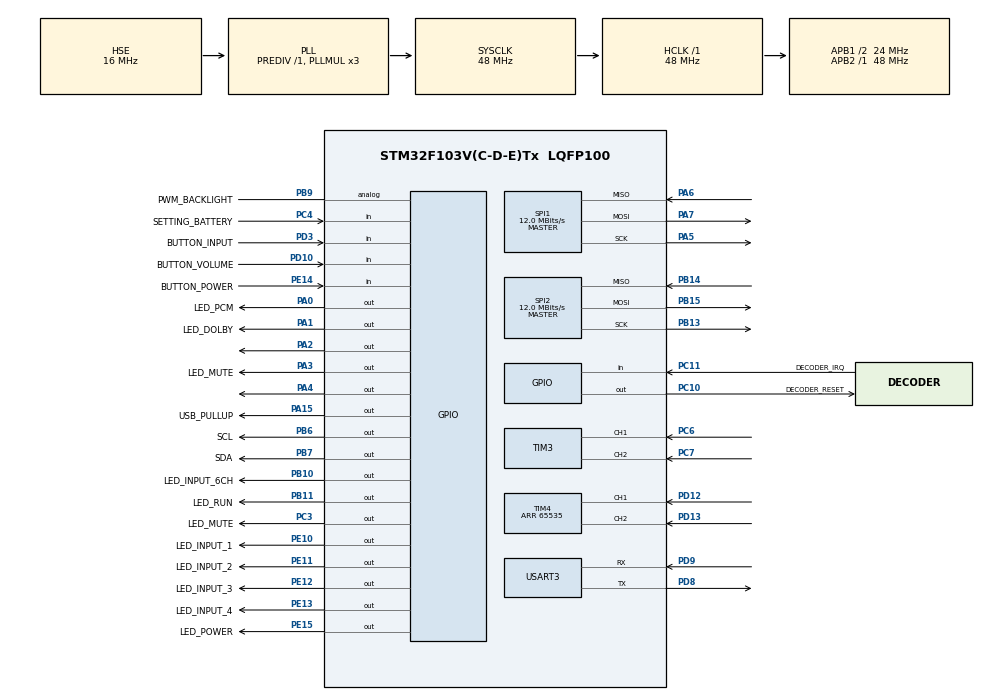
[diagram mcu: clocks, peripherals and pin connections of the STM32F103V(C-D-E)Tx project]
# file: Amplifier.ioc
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FREERTOS.Tasks01=defaultTask,24,256,StartDefaultTask,Default,NULL,Dynamic,NULL,NULL;audioThread,32,256,startAudio,Default,NULL,Dynamic,NULL,NULL
FREERTOS.configMINIMAL_STACK_SIZE=256
FREERTOS.configTOTAL_HEAP_SIZE=4096
FREERTOS.configUSE_NEWLIB_REENTRANT=1
Mcu.Family=STM32F1
Mcu.Name=STM32F103V(C-D-E)Tx
Mcu.Package=LQFP100
NVIC.PriorityGroup=NVIC_PRIORITYGROUP_4
NVIC.TIM3_IRQn=true\:5\:0\:false\:false\:true\:true\:true\:true\:true
NVIC.TIM4_IRQn=true\:5\:0\:false\:false\:true\:true\:true\:true\:true
OSC_IN.Mode=HSE-External-Oscillator
OSC_IN.Signal=RCC_OSC_IN
OSC_OUT.Mode=HSE-External-Oscillator
OSC_OUT.Signal=RCC_OSC_OUT
PA0-WKUP.GPIO_Label=LED_PCM
PA0-WKUP.Signal=GPIO_Output
PA1.GPIO_Label=LED_DOLBY
PA1.Signal=GPIO_Output
PA13.Mode=Serial_Wire
PA13.Signal=SYS_JTMS-SWDIO
PA14.Mode=Serial_Wire
PA14.Signal=SYS_JTCK-SWCLK
PA15.GPIO_Label=USB_PULLUP
PA15.Signal=GPIO_Output
PA2.Signal=GPIO_Output
PA3.GPIO_Label=LED_MUTE
PA3.Signal=GPIO_Output
PA4.Signal=GPIO_Output
PA5.Mode=Full_Duplex_Master
PA5.Signal=SPI1_SCK
PA6.Mode=Full_Duplex_Master
PA6.Signal=SPI1_MISO
PA7.Mode=Full_Duplex_Master
PA7.Signal=SPI1_MOSI
PB10.GPIO_Label=LED_INPUT_6CH
PB10.Signal=GPIO_Output
PB11.GPIO_Label=LED_RUN
PB11.Signal=GPIO_Output
PB13.Mode=Full_Duplex_Master
PB13.Signal=SPI2_SCK
PB14.Mode=Full_Duplex_Master
PB14.Signal=SPI2_MISO
PB15.Mode=Full_Duplex_Master
PB15.Signal=SPI2_MOSI
PB6.GPIO_Label=SCL
PB6.GPIO_ModeDefaultOutputPP=GPIO_MODE_OUTPUT_OD
PB6.GPIO_PuPd=GPIO_NOPULL
PB6.GPIO_Speed=GPIO_SPEED_FREQ_HIGH
PB6.PinState=GPIO_PIN_SET
PB6.Signal=GPIO_Output
PB7.GPIO_Label=SDA
PB7.GPIO_ModeDefaultOutputPP=GPIO_MODE_OUTPUT_OD
PB7.GPIO_PuPd=GPIO_NOPULL
PB7.GPIO_Speed=GPIO_SPEED_FREQ_HIGH
PB7.PinState=GPIO_PIN_SET
PB7.Signal=GPIO_Output
PB9.GPIO_Label=PWM_BACKLIGHT
PB9.Signal=GPIO_Analog
PC10.GPIO_Label=DECODER_RESET
PC10.PinState=GPIO_PIN_SET
PC10.Signal=GPIO_Output
PC11.GPIO_Label=DECODER_IRQ
PC11.Signal=GPIO_Input
PC14-OSC32_IN.Mode=LSE-External-Oscillator
PC14-OSC32_IN.Signal=RCC_OSC32_IN
PC15-OSC32_OUT.Mode=LSE-External-Oscillator
PC15-OSC32_OUT.Signal=RCC_OSC32_OUT
PC3.GPIO_Label=LED_MUTE
PC3.Signal=GPIO_Output
PC4.GPIO_Label=SETTING_BATTERY
PC4.Signal=GPIO_Input
PC6.Signal=S_TIM3_CH1
PC7.Signal=S_TIM3_CH2
PD10.GPIO_Label=BUTTON_VOLUME
PD10.GPIO_PuPd=GPIO_PULLUP
PD10.Signal=GPIO_Input
PD12.Signal=S_TIM4_CH1
PD13.Signal=S_TIM4_CH2
PD3.GPIO_Label=BUTTON_INPUT
PD3.GPIO_PuPd=GPIO_PULLUP
PD3.Signal=GPIO_Input
PD8.Mode=Asynchronous
PD8.Signal=USART3_TX
PD9.Mode=Asynchronous
PD9.Signal=USART3_RX
PE10.GPIO_Label=LED_INPUT_1
PE10.Signal=GPIO_Output
PE11.GPIO_Label=LED_INPUT_2
PE11.Signal=GPIO_Output
PE12.GPIO_Label=LED_INPUT_3
PE12.Signal=GPIO_Output
PE13.GPIO_Label=LED_INPUT_4
PE13.Signal=GPIO_Output
PE14.GPIO_Label=BUTTON_POWER
PE14.Signal=GPIO_Input
PE15.GPIO_Label=LED_POWER
PE15.Signal=GPIO_Output
ProjectManager.HeapSize=0x200
ProjectManager.StackSize=0x400
ProjectManager.TargetToolchain=STM32CubeIDE
RCC.AHBFreq_Value=48000000
RCC.APB1CLKDivider=RCC_HCLK_DIV2
RCC.APB1Freq_Value=24000000
RCC.APB1TimFreq_Value=48000000
RCC.APB2Freq_Value=48000000
RCC.APB2TimFreq_Value=48000000
RCC.HCLKFreq_Value=48000000
RCC.HSE_VALUE=16000000
RCC.PLLMUL=RCC_PLL_MUL3
RCC.PLLSourceVirtual=RCC_PLLSOURCE_HSE
RCC.RTCClockSelection=RCC_RTCCLKSOURCE_LSE
RCC.SYSCLKFreq_VALUE=48000000
RCC.SYSCLKSource=RCC_SYSCLKSOURCE_PLLCLK
RCC.USBFreq_Value=48000000
SH.S_TIM3_CH1.0=TIM3_CH1,Encoder_Interface
SH.S_TIM3_CH2.0=TIM3_CH2,Encoder_Interface
SH.S_TIM4_CH1.0=TIM4_CH1,Encoder_Interface
SH.S_TIM4_CH2.0=TIM4_CH2,Encoder_Interface
SPI1.BaudRatePrescaler=SPI_BAUDRATEPRESCALER_4
SPI1.CalculateBaudRate=12.0 MBits/s
SPI1.Direction=SPI_DIRECTION_2LINES
SPI1.Mode=SPI_MODE_MASTER
SPI1.VirtualType=VM_MASTER
SPI2.BaudRatePrescaler=SPI_BAUDRATEPRESCALER_2
SPI2.CalculateBaudRate=12.0 MBits/s
SPI2.Direction=SPI_DIRECTION_2LINES
SPI2.Mode=SPI_MODE_MASTER
SPI2.VirtualType=VM_MASTER
TIM4.AutoReloadPreload=TIM_AUTORELOAD_PRELOAD_ENABLE
TIM4.ClockDivision=TIM_CLOCKDIVISION_DIV1
TIM4.EncoderMode=TIM_ENCODERMODE_TI12
TIM4.IC1Filter=5
TIM4.IC1Prescaler=TIM_ICPSC_DIV1
TIM4.IC2Filter=5
TIM4.IC2Polarity=TIM_ICPOLARITY_RISING
TIM4.IC2Prescaler=TIM_ICPSC_DIV1
TIM4.Period=65535
TIM4.TIM_MasterOutputTrigger=TIM_TRGO_RESET
USART3.VirtualMode=VM_ASYNC
VP_FREERTOS_VS_CMSIS_V2.Mode=CMSIS_V2
board=custom

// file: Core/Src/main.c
/* USER CODE BEGIN Header */
/**
  ******************************************************************************
  * @file           : main.c
  * @brief          : Main program body
  ******************************************************************************
  * @attention
  *
  * Copyright (c) 2023 STMicroelectronics.
  * All rights reserved.
  *
  * This software is licensed under terms that can be found in the LICENSE file
  * in the root directory of this software component.
  * If no LICENSE file comes with this software, it is provided AS-IS.
  *
  ******************************************************************************
  */
/* USER CODE END Header */
#include "main.h"
#include "cmsis_os.h"

/* USER CODE BEGIN Includes */

#include "Amplifier.h"
#include "Debug.h"
#include "Delay.h"

/* USER CODE END Includes */

SPI_HandleTypeDef hspi1;
SPI_HandleTypeDef hspi2;

TIM_HandleTypeDef htim3;
TIM_HandleTypeDef htim4;

UART_HandleTypeDef huart3;

/* Definitions for defaultTask */
osThreadId_t defaultTaskHandle;
const osThreadAttr_t defaultTask_attributes = {
  .name = "defaultTask",
  .stack_size = 256 * 4,
  .priority = (osPriority_t) osPriorityNormal,
};
/* Definitions for audioThread */
osThreadId_t audioThreadHandle;
const osThreadAttr_t audioThread_attributes = {
  .name = "audioThread",
  .stack_size = 256 * 4,
  .priority = (osPriority_t) osPriorityAboveNormal,
};

void SystemClock_Config(void);
static void MX_GPIO_Init(void);
static void MX_SPI1_Init(void);
static void MX_SPI2_Init(void);
static void MX_TIM3_Init(void);
static void MX_TIM4_Init(void);
static void MX_USART3_UART_Init(void);
void StartDefaultTask(void *argument);
void startAudio(void *argument);

/* USER CODE BEGIN 0 */

// Global amplifier variable
Amplifier amplifier;

/* USER CODE END 0 */

int main(void)
{

  /* MCU Configuration--------------------------------------------------------*/

  /* Reset of all peripherals, Initializes the Flash interface and the Systick. */
  HAL_Init();

  /* Configure the system clock */
  SystemClock_Config();

  /* Initialize all configured peripherals */
  MX_GPIO_Init();
  MX_SPI1_Init();
  MX_SPI2_Init();
  MX_TIM3_Init();
  MX_TIM4_Init();
  MX_USART3_UART_Init();
  /* USER CODE BEGIN 2 */

  DEBUG_UART = huart3;

  DEBUG_STR( "Starting" );

  DWT_Delay_Init();

  // The main amplifier class
  amplifier.initialize();
//  amplifier.getAudio().preTick();

  /* USER CODE END 2 */

  /* Init scheduler */
  osKernelInitialize();

  /* Create the thread(s) */
  /* creation of defaultTask */
  defaultTaskHandle = osThreadNew(StartDefaultTask, NULL, &defaultTask_attributes);

  /* creation of audioThread */
  audioThreadHandle = osThreadNew(startAudio, NULL, &audioThread_attributes);

  /* Start scheduler */
  osKernelStart();

  /* We should never get here as control is now taken by the scheduler */
  /* Infinite loop */
  while (1)
  {

  }
}

void SystemClock_Config(void)
{
  RCC_OscInitTypeDef RCC_OscInitStruct = {0};
  RCC_ClkInitTypeDef RCC_ClkInitStruct = {0};

  /** Initializes the RCC Oscillators according to the specified parameters
  * in the RCC_OscInitTypeDef structure.
  */
  RCC_OscInitStruct.OscillatorType = RCC_OSCILLATORTYPE_HSE;
  RCC_OscInitStruct.HSEState = RCC_HSE_ON;
  RCC_OscInitStruct.HSEPredivValue = RCC_HSE_PREDIV_DIV1;
  RCC_OscInitStruct.HSIState = RCC_HSI_ON;
  RCC_OscInitStruct.PLL.PLLState = RCC_PLL_ON;
  RCC_OscInitStruct.PLL.PLLSource = RCC_PLLSOURCE_HSE;
  RCC_OscInitStruct.PLL.PLLMUL = RCC_PLL_MUL3;
  if (HAL_RCC_OscConfig(&RCC_OscInitStruct) != HAL_OK)
  {
    Error_Handler();
  }

  /** Initializes the CPU, AHB and APB buses clocks
  */
  RCC_ClkInitStruct.ClockType = RCC_CLOCKTYPE_HCLK|RCC_CLOCKTYPE_SYSCLK
                              |RCC_CLOCKTYPE_PCLK1|RCC_CLOCKTYPE_PCLK2;
  RCC_ClkInitStruct.SYSCLKSource = RCC_SYSCLKSOURCE_PLLCLK;
  RCC_ClkInitStruct.AHBCLKDivider = RCC_SYSCLK_DIV1;
  RCC_ClkInitStruct.APB1CLKDivider = RCC_HCLK_DIV2;
  RCC_ClkInitStruct.APB2CLKDivider = RCC_HCLK_DIV1;

  if (HAL_RCC_ClockConfig(&RCC_ClkInitStruct, FLASH_LATENCY_1) != HAL_OK)
  {
    Error_Handler();
  }
}

static void MX_SPI1_Init(void)
{

  /* SPI1 parameter configuration*/
  hspi1.Instance = SPI1;
  hspi1.Init.Mode = SPI_MODE_MASTER;
  hspi1.Init.Direction = SPI_DIRECTION_2LINES;
  hspi1.Init.DataSize = SPI_DATASIZE_8BIT;
  hspi1.Init.CLKPolarity = SPI_POLARITY_LOW;
  hspi1.Init.CLKPhase = SPI_PHASE_1EDGE;
  hspi1.Init.NSS = SPI_NSS_SOFT;
  hspi1.Init.BaudRatePrescaler = SPI_BAUDRATEPRESCALER_4;
  hspi1.Init.FirstBit = SPI_FIRSTBIT_MSB;
  hspi1.Init.TIMode = SPI_TIMODE_DISABLE;
  hspi1.Init.CRCCalculation = SPI_CRCCALCULATION_DISABLE;
  hspi1.Init.CRCPolynomial = 10;
  if (HAL_SPI_Init(&hspi1) != HAL_OK)
  {
    Error_Handler();
  }

}

static void MX_SPI2_Init(void)
{

  /* SPI2 parameter configuration*/
  hspi2.Instance = SPI2;
  hspi2.Init.Mode = SPI_MODE_MASTER;
  hspi2.Init.Direction = SPI_DIRECTION_2LINES;
  hspi2.Init.DataSize = SPI_DATASIZE_8BIT;
  hspi2.Init.CLKPolarity = SPI_POLARITY_LOW;
  hspi2.Init.CLKPhase = SPI_PHASE_1EDGE;
  hspi2.Init.NSS = SPI_NSS_SOFT;
  hspi2.Init.BaudRatePrescaler = SPI_BAUDRATEPRESCALER_2;
  hspi2.Init.FirstBit = SPI_FIRSTBIT_MSB;
  hspi2.Init.TIMode = SPI_TIMODE_DISABLE;
  hspi2.Init.CRCCalculation = SPI_CRCCALCULATION_DISABLE;
  hspi2.Init.CRCPolynomial = 10;
  if (HAL_SPI_Init(&hspi2) != HAL_OK)
  {
    Error_Handler();
  }

}

static void MX_TIM3_Init(void)
{

  TIM_Encoder_InitTypeDef sConfig = {0};
  TIM_MasterConfigTypeDef sMasterConfig = {0};

  htim3.Instance = TIM3;
  htim3.Init.Prescaler = 0;
  htim3.Init.CounterMode = TIM_COUNTERMODE_UP;
  htim3.Init.Period = 65535;
  htim3.Init.ClockDivision = TIM_CLOCKDIVISION_DIV1;
  htim3.Init.AutoReloadPreload = TIM_AUTORELOAD_PRELOAD_DISABLE;
  sConfig.EncoderMode = TIM_ENCODERMODE_TI1;
  sConfig.IC1Polarity = TIM_ICPOLARITY_RISING;
  sConfig.IC1Selection = TIM_ICSELECTION_DIRECTTI;
  sConfig.IC1Prescaler = TIM_ICPSC_DIV1;
  sConfig.IC1Filter = 0;
  sConfig.IC2Polarity = TIM_ICPOLARITY_RISING;
  sConfig.IC2Selection = TIM_ICSELECTION_DIRECTTI;
  sConfig.IC2Prescaler = TIM_ICPSC_DIV1;
  sConfig.IC2Filter = 0;
  if (HAL_TIM_Encoder_Init(&htim3, &sConfig) != HAL_OK)
  {
    Error_Handler();
  }
  sMasterConfig.MasterOutputTrigger = TIM_TRGO_RESET;
  sMasterConfig.MasterSlaveMode = TIM_MASTERSLAVEMODE_DISABLE;
  if (HAL_TIMEx_MasterConfigSynchronization(&htim3, &sMasterConfig) != HAL_OK)
  {
    Error_Handler();
  }

}

static void MX_TIM4_Init(void)
{

  TIM_Encoder_InitTypeDef sConfig = {0};
  TIM_MasterConfigTypeDef sMasterConfig = {0};

  htim4.Instance = TIM4;
  htim4.Init.Prescaler = 0;
  htim4.Init.CounterMode = TIM_COUNTERMODE_UP;
  htim4.Init.Period = 65535;
  htim4.Init.ClockDivision = TIM_CLOCKDIVISION_DIV1;
  htim4.Init.AutoReloadPreload = TIM_AUTORELOAD_PRELOAD_ENABLE;
  sConfig.EncoderMode = TIM_ENCODERMODE_TI12;
  sConfig.IC1Polarity = TIM_ICPOLARITY_RISING;
  sConfig.IC1Selection = TIM_ICSELECTION_DIRECTTI;
  sConfig.IC1Prescaler = TIM_ICPSC_DIV1;
  sConfig.IC1Filter = 5;
  sConfig.IC2Polarity = TIM_ICPOLARITY_RISING;
  sConfig.IC2Selection = TIM_ICSELECTION_DIRECTTI;
  sConfig.IC2Prescaler = TIM_ICPSC_DIV1;
  sConfig.IC2Filter = 5;
  if (HAL_TIM_Encoder_Init(&htim4, &sConfig) != HAL_OK)
  {
    Error_Handler();
  }
  sMasterConfig.MasterOutputTrigger = TIM_TRGO_RESET;
  sMasterConfig.MasterSlaveMode = TIM_MASTERSLAVEMODE_DISABLE;
  if (HAL_TIMEx_MasterConfigSynchronization(&htim4, &sMasterConfig) != HAL_OK)
  {
    Error_Handler();
  }
  /* USER CODE BEGIN TIM4_Init 2 */

	// Star the volume control timer
	HAL_TIM_Encoder_Start_IT( &htim4, TIM_CHANNEL_ALL );

  /* USER CODE END TIM4_Init 2 */

}

static void MX_USART3_UART_Init(void)
{

  huart3.Instance = USART3;
  huart3.Init.BaudRate = 115200;
  huart3.Init.WordLength = UART_WORDLENGTH_8B;
  huart3.Init.StopBits = UART_STOPBITS_1;
  huart3.Init.Parity = UART_PARITY_NONE;
  huart3.Init.Mode = UART_MODE_TX_RX;
  huart3.Init.HwFlowCtl = UART_HWCONTROL_NONE;
  huart3.Init.OverSampling = UART_OVERSAMPLING_16;
  if (HAL_UART_Init(&huart3) != HAL_OK)
  {
    Error_Handler();
  }

}

static void MX_GPIO_Init(void)
{
  GPIO_InitTypeDef GPIO_InitStruct = {0};

  /* GPIO Ports Clock Enable */
  __HAL_RCC_GPIOC_CLK_ENABLE();
  __HAL_RCC_GPIOA_CLK_ENABLE();
  __HAL_RCC_GPIOE_CLK_ENABLE();
  __HAL_RCC_GPIOB_CLK_ENABLE();
  __HAL_RCC_GPIOD_CLK_ENABLE();

  /*Configure GPIO pin Output Level */
  HAL_GPIO_WritePin(LED_MUTE_GPIO_Port, LED_MUTE_Pin, GPIO_PIN_RESET);

  /*Configure GPIO pin Output Level */
  HAL_GPIO_WritePin(GPIOA, LED_PCM_Pin|LED_DOLBY_Pin|GPIO_PIN_2|LED_MUTEA3_Pin
                          |GPIO_PIN_4|USB_PULLUP_Pin, GPIO_PIN_RESET);

  /*Configure GPIO pin Output Level */
  HAL_GPIO_WritePin(GPIOE, LED_INPUT_1_Pin|LED_INPUT_2_Pin|LED_INPUT_3_Pin|LED_INPUT_4_Pin
                          |LED_POWER_Pin, GPIO_PIN_RESET);

  /*Configure GPIO pin Output Level */
  HAL_GPIO_WritePin(GPIOB, LED_INPUT_6CH_Pin|LED_RUN_Pin, GPIO_PIN_RESET);

  /*Configure GPIO pin Output Level */
  HAL_GPIO_WritePin(DECODER_RESET_GPIO_Port, DECODER_RESET_Pin, GPIO_PIN_SET);

  /*Configure GPIO pin Output Level */
  HAL_GPIO_WritePin(GPIOB, SCL_Pin|SDA_Pin, GPIO_PIN_SET);

  /*Configure GPIO pins : LED_MUTE_Pin DECODER_RESET_Pin */
  GPIO_InitStruct.Pin = LED_MUTE_Pin|DECODER_RESET_Pin;
  GPIO_InitStruct.Mode = GPIO_MODE_OUTPUT_PP;
  GPIO_InitStruct.Pull = GPIO_NOPULL;
  GPIO_InitStruct.Speed = GPIO_SPEED_FREQ_LOW;
  HAL_GPIO_Init(GPIOC, &GPIO_InitStruct);

  /*Configure GPIO pins : LED_PCM_Pin LED_DOLBY_Pin PA2 LED_MUTEA3_Pin
                           PA4 USB_PULLUP_Pin */
  GPIO_InitStruct.Pin = LED_PCM_Pin|LED_DOLBY_Pin|GPIO_PIN_2|LED_MUTEA3_Pin
                          |GPIO_PIN_4|USB_PULLUP_Pin;
  GPIO_InitStruct.Mode = GPIO_MODE_OUTPUT_PP;
  GPIO_InitStruct.Pull = GPIO_NOPULL;
  GPIO_InitStruct.Speed = GPIO_SPEED_FREQ_LOW;
  HAL_GPIO_Init(GPIOA, &GPIO_InitStruct);

  /*Configure GPIO pins : SETTING_BATTERY_Pin DECODER_IRQ_Pin */
  GPIO_InitStruct.Pin = SETTING_BATTERY_Pin|DECODER_IRQ_Pin;
  GPIO_InitStruct.Mode = GPIO_MODE_INPUT;
  GPIO_InitStruct.Pull = GPIO_NOPULL;
  HAL_GPIO_Init(GPIOC, &GPIO_InitStruct);

  /*Configure GPIO pins : LED_INPUT_1_Pin LED_INPUT_2_Pin LED_INPUT_3_Pin LED_INPUT_4_Pin
                           LED_POWER_Pin */
  GPIO_InitStruct.Pin = LED_INPUT_1_Pin|LED_INPUT_2_Pin|LED_INPUT_3_Pin|LED_INPUT_4_Pin
                          |LED_POWER_Pin;
  GPIO_InitStruct.Mode = GPIO_MODE_OUTPUT_PP;
  GPIO_InitStruct.Pull = GPIO_NOPULL;
  GPIO_InitStruct.Speed = GPIO_SPEED_FREQ_LOW;
  HAL_GPIO_Init(GPIOE, &GPIO_InitStruct);

  /*Configure GPIO pin : BUTTON_POWER_Pin */
  GPIO_InitStruct.Pin = BUTTON_POWER_Pin;
  GPIO_InitStruct.Mode = GPIO_MODE_INPUT;
  GPIO_InitStruct.Pull = GPIO_NOPULL;
  HAL_GPIO_Init(BUTTON_POWER_GPIO_Port, &GPIO_InitStruct);

  /*Configure GPIO pins : LED_INPUT_6CH_Pin LED_RUN_Pin */
  GPIO_InitStruct.Pin = LED_INPUT_6CH_Pin|LED_RUN_Pin;
  GPIO_InitStruct.Mode = GPIO_MODE_OUTPUT_PP;
  GPIO_InitStruct.Pull = GPIO_NOPULL;
  GPIO_InitStruct.Speed = GPIO_SPEED_FREQ_LOW;
  HAL_GPIO_Init(GPIOB, &GPIO_InitStruct);

  /*Configure GPIO pins : BUTTON_VOLUME_Pin BUTTON_INPUT_Pin */
  GPIO_InitStruct.Pin = BUTTON_VOLUME_Pin|BUTTON_INPUT_Pin;
  GPIO_InitStruct.Mode = GPIO_MODE_INPUT;
  GPIO_InitStruct.Pull = GPIO_PULLUP;
  HAL_GPIO_Init(GPIOD, &GPIO_InitStruct);

  /*Configure GPIO pins : SCL_Pin SDA_Pin */
  GPIO_InitStruct.Pin = SCL_Pin|SDA_Pin;
  GPIO_InitStruct.Mode = GPIO_MODE_OUTPUT_OD;
  GPIO_InitStruct.Pull = GPIO_NOPULL;
  GPIO_InitStruct.Speed = GPIO_SPEED_FREQ_HIGH;
  HAL_GPIO_Init(GPIOB, &GPIO_InitStruct);

  /*Configure GPIO pin : PWM_BACKLIGHT_Pin */
  GPIO_InitStruct.Pin = PWM_BACKLIGHT_Pin;
  GPIO_InitStruct.Mode = GPIO_MODE_ANALOG;
  HAL_GPIO_Init(PWM_BACKLIGHT_GPIO_Port, &GPIO_InitStruct);

}

void StartDefaultTask(void *argument)
{
  /* USER CODE BEGIN 5 */
  /* Infinite loop */

	amplifier.preTick();

  for(;;)
  {
	amplifier.tick();
    osDelay(1);
  }
  /* USER CODE END 5 */
}

void startAudio(void *argument)
{
  /* USER CODE BEGIN startAudio */
	amplifier.getAudio().preTick();

  /* Infinite loop */
  for(;;)
  {
	amplifier.getAudio().tick();
    osDelay(1);
  }
  /* USER CODE END startAudio */
}

void Error_Handler(void)
{
  __disable_irq();
  while (1)
  {
  }
}
